# LPC83x register map
File version: 0.2
CPU: CM0PLUS r0p1, little endian, no MPU, no FPU, 2 interrupt priority bits
Registers are 32-bit, read-write, reset 0x0 unless marked. A register's access mark holds for its fields unless they carry their own. Offsets are from the block's base; [hi:lo] are bit positions; {n}, {i} and the like mark numbered series.

## DMATRIGMUX — DMA trigger mux
Base 0x40028000
{0x0+4i} DMA_ITRIG_INMUX{i} (i=0..17) reset 0xF — Trigger select register for DMA channels 0 to 17.
  [3:0] INP — Trigger input number (decimal value) for DMA channel n (n = 0 to 8). All other values are reserved.
    0=ADC_SEQA_IRQ; 1=ADC_SEQB_IRQ; 2=SCT_DMA0; 3=SCT_DMA1; 5=PININT0; 6=PININT1; 7=DMA_TRIGGER_MUX_0 (DMA trigger mux 0. (DMA_INMUX_INMUX0).); 8=DMA_TRIGGER_MUX_1 (DMA trigger mux 1. (DMA_INMUX_INMUX1))

## INPUTMUX — Input multiplexing
Base 0x4002C000
{0x0+4i} DMA_INMUX_INMUX{i} (i=0..1) reset 0x1F — DMA output trigger selection to become DMA trigger.
  [4:0] INP — DMA trigger output number (decimal value) for DMA channel n (n = 0 to 11).
{0x20+4i} SCT0_INMUX{i} (i=0..3) reset 0xF — Input mux register for SCT inputs
  [3:0] INP_N — Input number (decimal value) to SCT0 inputs 0 to 3.
    0=SCT_IN0_CHANGE_THE (SCT_IN0 change the name since this is not the function sct_in0 but the first selection for sct input in the mux.in fact it could be functionally sct_in3 (input 3 of the sct). Assign to pin using the switch matrix.); 1=SCT_IN1 (SCT_IN1. Assign to pin using the switch matrix.); 2=SCT_IN2 (SCT_IN2. Assign to pin using the switch matrix.); 3=SCT_IN3 (SCT_IN3. Assign to pin using the switch matrix.); 4=ADC_THCMP_IRQ; 6=ARM_TXEV; 7=DEBUG_HALTED

## FLASHCTRL — Flash controller
Base 0x40040000
0x10 FLASHCFG reset not defined — Flash configuration register
  [1:0] FLASHTIM — Flash memory access time. FLASHTIM +1 is equal to the number of system clocks used for flash access.
    0=1_SYSTEM_CLOCK_FLASH (1 system clock flash access time (for system clock frequencies of up to 20 MHz).); 1=2_SYSTEM_CLOCKS_FLAS (2 system clocks flash access time (for system clock frequencies of up to 30 MHz).)
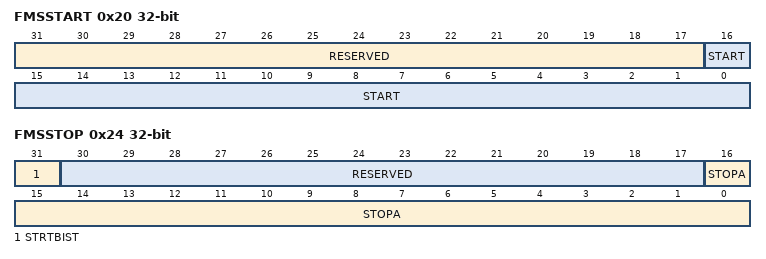
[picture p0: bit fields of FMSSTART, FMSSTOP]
0x20 FMSSTART — Signature start address register
  [31:17] RESERVED — Reserved, user software should not write ones to reserved bits. The value read from a reserved bit is not defined.
  [16:0] START — Signature generation start address (corresponds to AHB byte address bits[20:4]).
0x24 FMSSTOP — Signature stop-address register
  [31] STRTBIST — When this bit is written to 1, signature generation starts. At the end of signature generation, this bit is automatically cleared.
  [30:17] RESERVED — Reserved, user software should not write ones to reserved bits. The value read from a reserved bit is not defined.
  [16:0] STOPA — Stop address for signature generation (the word specified by STOPA is included in the address range). The address is in units of memory words, not bytes. If the option bistprotection=1, bits 2:0 cannot be written and are forced to 111.
0x2C FMSW0 ro reset not defined — Signature Word
  [31:0] SIG — 32-bit signature.

## CRC — Cyclic Redundancy Check (CRC) engine
Base 0x50000000
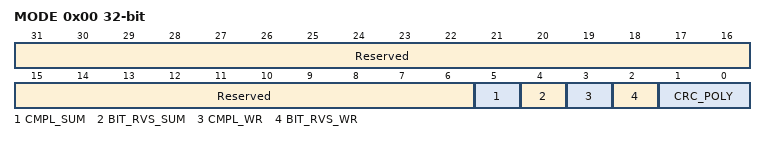
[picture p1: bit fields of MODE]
0x00 MODE — CRC mode register
  [31:6] Reserved — Always 0 when read
  [5] CMPL_SUM — CRC sum complement: 1= 1's complement for CRC_SUM 0=No 1's complement for CRC_SUM
  [4] BIT_RVS_SUM — CRC sum bit order: 1= Bit order reverse for CRC_SUM 0= No bit order reverse for CRC_SUM
  [3] CMPL_WR — Data complement: 1= 1's complement for CRC_WR_DATA 0= No 1's complement for CRC_WR_DATA
  [2] BIT_RVS_WR — Data bit order: 1= Bit order reverse for CRC_WR_DATA (per byte) 0= No bit order reverse for CRC_WR_DATA (per byte)
  [1:0] CRC_POLY — CRC polynom: 1X= CRC-32 polynomial 01= CRC-16 polynomial 00= CRC-CCITT polynomial
0x04 SEED reset 0xFFFF — CRC seed register
  [31:0] CRC_SEED — A write access to this register will load CRC seed value to CRC_SUM register with selected bit order and 1's complement pre-processes. A write access to this register will overrule the CRC calculation in progresses.
0x08 SUM ro reset 0xFFFF — CRC checksum register
  [31:0] CRC_SUM — The most recent CRC sum can be read through this register with selected bit order and 1's complement post-processes.
0x08 WR_DATA wo reset not defined (alternate view of SUM) — CRC data register
  [31:0] CRC_WR_DATA — Data written to this register will be taken to perform CRC calculation with selected bit order and 1's complement pre-process. Any write size 8, 16 or 32-bit are allowed and accept back-to-back transactions.

## GPIO_PORT — General Purpose I/O port (GPIO)
Base 0xA0000000
{0x0+i} B{i} (i=0..28) 1-bit reset not defined — Byte pin registers port 0; pins PIO0_0 to PIO0_28
  [0] PBYTE — Read: state of the pin PIO0_n, regardless of direction, masking, or alternate function, except that pins configured as analog I/O always read as 0. One register for each port pin: n = pin 0 to 28. Write: loads the pin's output bit.
{0x1000+4i} W{i} (i=0..28) reset not defined — Word pin registers port 0
  [31:0] PWORD — Read 0: pin PIOm_n is LOW. Write 0: clear output bit. Read 0xFFFF FFFF: pin PIOm_n is HIGH. Write any value 0x0000 0001 to 0xFFFF FFFF: set output bit. Only 0 or 0xFFFF FFFF can be read. Writing any value other than 0 will set the output bit. One register for each port pin: n = pin 0 to 28.
0x2000 DIR0 — Direction registers port 0
  [28:0] DIRP — Selects pin direction for pin PIO0_n (bit 0 = PIO0_0, bit 1 = PIO0_1, ..., bit 28 = PIO0_28). 0 = input. 1 = output.
0x2080 MASK0 — Mask register port 0
  [28:0] MASKP — Controls which bits corresponding to PIO0_n are active in the MPORT register (bit 0 = PIO0_0, bit 1 = PIO0_1, ..., bit 28 = PIO0_28). 0 = Read MPORT: pin state; write MPORT: load output bit. 1 = Read MPORT: 0; write MPORT: output bit not affected.
0x2100 PIN0 reset not defined — Port pin register port 0
  [28:0] PORT — Reads pin states or loads output bits (bit 0 = PIO0_0, bit 1 = PIO0_1, ..., bit 38 = PIO0_28). 0 = Read: pin is low; write: clear output bit. 1 = Read: pin is high; write: set output bit.
0x2180 MPIN0 reset not defined — Masked port register port 0
  [28:0] MPORTP — Masked port register (bit 0 = PIO0_0, bit 1 =PIO0_1, ..., bit 28 = PIO0_28). 0 = Read: pin is LOW and/or the corresponding bit in the MASK register is 1; write: clear output bit if the corresponding bit in the MASK register is 0. 1 = Read: pin is HIGH and the corresponding bit in the MASK register is 0; write: set output bit if the corresponding bit in the MASK register is 0.
0x2200 SET0 — Write: Set register for port 0 Read: output bits for port 0
  [28:0] SETP — Read or set output bits (bit 0 = PIO0_0, bit 1 =PIO0_1, ..., bit 28 = PIO0_28). 0 = Read: output bit: write: no operation. 1 = Read: output bit; write: set output bit.
0x2280 CLR0 wo reset not defined — Clear port 0
  [28:0] CLRP — Clear output bits (bit 0 = PIO0_0, bit 1 =PIO0_1, ..., bit 28 = PIO0_28). 0 = No operation. 1 = Clear output bit.
0x2300 NOT0 wo reset not defined — Toggle port 0
  [28:0] NOTP — Toggle output bits (bit 0 = PIO0_0, bit 1 =PIO0_1, ..., bit 28 = PIO0_28). 0 = no operation. 1 = Toggle output bit.
0x2380 DIRSET0 wo — Set pin direction bits for port 0.
  [28:0] DIRSETP — Set direction bits (bit 0 = PIO0_0, bit 1 = PIO0_1, ..., bit 28 = PIO0_28). 0 = No operation. 1 = Set direction bit.
0x2400 DIRCLR0 wo reset not defined — Clear pin direction bits for port 0.
  [28:0] DIRCLRP — Clear direction bits (bit 0 = PIO0_0, bit 1 =PIO0_1, ..., bit 28 = PIO0_28). 0 = No operation. 1 = Clear direction bit.
0x2480 DIRNOT0 wo reset not defined — Toggle pin direction bits for port 0.
  [28:0] DIRNOTP — Toggle direction bits (bit 0 = PIO0_0, bit 1 =PIO0_1, ..., bit 28 = PIO0_28). 0 = no operation. 1 = Toggle direction bit.
